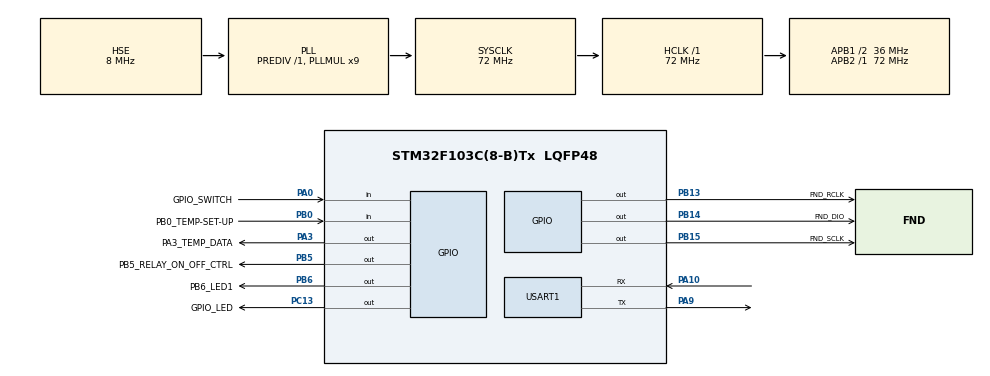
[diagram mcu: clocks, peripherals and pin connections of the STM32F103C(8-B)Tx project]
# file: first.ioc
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Mcu.Family=STM32F1
Mcu.Name=STM32F103C(8-B)Tx
Mcu.Package=LQFP48
NVIC.PriorityGroup=NVIC_PRIORITYGROUP_4
NVIC.TIM2_IRQn=true\:0\:0\:false\:false\:true\:true\:true\:true
PA0-WKUP.GPIO_Label=GPIO_SWITCH
PA0-WKUP.GPIO_PuPd=GPIO_PULLUP
PA0-WKUP.Signal=GPIO_Input
PA10.Mode=Asynchronous
PA10.Signal=USART1_RX
PA13.Mode=Serial_Wire
PA13.Signal=SYS_JTMS-SWDIO
PA14.Mode=Serial_Wire
PA14.Signal=SYS_JTCK-SWCLK
PA3.GPIO_Label=PA3_TEMP_DATA
PA3.GPIO_ModeDefaultOutputPP=GPIO_MODE_OUTPUT_PP
PA3.GPIO_PuPd=GPIO_PULLUP
PA3.GPIO_Speed=GPIO_SPEED_FREQ_HIGH
PA3.PinState=GPIO_PIN_SET
PA3.Signal=GPIO_Output
PA9.Mode=Asynchronous
PA9.Signal=USART1_TX
PB0.GPIO_Label=PB0_TEMP-SET-UP
PB0.GPIO_Mode=GPIO_MODE_INPUT
PB0.GPIO_PuPd=GPIO_PULLUP
PB0.Signal=GPIO_Input
PB13.GPIO_Label=FND_RCLK
PB13.GPIO_ModeDefaultOutputPP=GPIO_MODE_OUTPUT_PP
PB13.GPIO_PuPd=GPIO_PULLUP
PB13.GPIO_Speed=GPIO_SPEED_FREQ_HIGH
PB13.PinState=GPIO_PIN_SET
PB13.Signal=GPIO_Output
PB14.GPIO_Label=FND_DIO
PB14.GPIO_ModeDefaultOutputPP=GPIO_MODE_OUTPUT_PP
PB14.GPIO_PuPd=GPIO_PULLUP
PB14.GPIO_Speed=GPIO_SPEED_FREQ_HIGH
PB14.PinState=GPIO_PIN_SET
PB14.Signal=GPIO_Output
PB15.GPIO_Label=FND_SCLK
PB15.GPIO_PuPd=GPIO_PULLUP
PB15.GPIO_Speed=GPIO_SPEED_FREQ_HIGH
PB15.PinState=GPIO_PIN_SET
PB15.Signal=GPIO_Output
PB5.GPIO_Label=PB5_RELAY_ON_OFF_CTRL
PB5.GPIO_ModeDefaultOutputPP=GPIO_MODE_OUTPUT_PP
PB5.GPIO_PuPd=GPIO_PULLDOWN
PB5.GPIO_Speed=GPIO_SPEED_FREQ_HIGH
PB5.PinState=GPIO_PIN_RESET
PB5.Signal=GPIO_Output
PB6.GPIO_Label=PB6_LED1
PB6.GPIO_PuPd=GPIO_PULLUP
PB6.PinState=GPIO_PIN_SET
PB6.Signal=GPIO_Output
PC13-TAMPER-RTC.GPIO_Label=GPIO_LED
PC13-TAMPER-RTC.GPIO_PuPd=GPIO_PULLUP
PC13-TAMPER-RTC.GPIO_Speed=GPIO_SPEED_FREQ_HIGH
PC13-TAMPER-RTC.PinState=GPIO_PIN_SET
PC13-TAMPER-RTC.Signal=GPIO_Output
PC14-OSC32_IN.Mode=LSE-External-Oscillator
PC14-OSC32_IN.Signal=RCC_OSC32_IN
PC15-OSC32_OUT.Mode=LSE-External-Oscillator
PC15-OSC32_OUT.Signal=RCC_OSC32_OUT
PD0-OSC_IN.Mode=HSE-External-Oscillator
PD0-OSC_IN.Signal=RCC_OSC_IN
PD1-OSC_OUT.Mode=HSE-External-Oscillator
PD1-OSC_OUT.Signal=RCC_OSC_OUT
ProjectManager.HeapSize=0x200
ProjectManager.StackSize=0x400
ProjectManager.TargetToolchain=STM32CubeIDE
RCC.AHBFreq_Value=72000000
RCC.APB1CLKDivider=RCC_HCLK_DIV2
RCC.APB1Freq_Value=36000000
RCC.APB1TimFreq_Value=72000000
RCC.APB2Freq_Value=72000000
RCC.APB2TimFreq_Value=72000000
RCC.HCLKFreq_Value=72000000
RCC.PLLMUL=RCC_PLL_MUL9
RCC.PLLSourceVirtual=RCC_PLLSOURCE_HSE
RCC.SYSCLKFreq_VALUE=72000000
RCC.SYSCLKSource=RCC_SYSCLKSOURCE_PLLCLK
RCC.USBFreq_Value=72000000
TIM2.AutoReloadPreload=TIM_AUTORELOAD_PRELOAD_DISABLE
TIM2.Period=0xFFFF
TIM2.Prescaler=(72-1)
USART1.VirtualMode=VM_ASYNC
VP_TIM2_VS_ClockSourceINT.Mode=Internal
board=custom

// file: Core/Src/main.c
/* USER CODE BEGIN Header */
/**
  ******************************************************************************
  * @file           : main.c
  * @brief          : Main program body
  ******************************************************************************
  * @attention
  *
  * <h2><center>&copy; Copyright (c) 2024 STMicroelectronics.
  * All rights reserved.</center></h2>
  *
  * This software component is licensed by ST under BSD 3-Clause license,
  * the "License"; You may not use this file except in compliance with the
  * License. You may obtain a copy of the License at:
  *                        opensource.org/licenses/BSD-3-Clause
  *
  ******************************************************************************
  */
/* USER CODE END Header */
#include "main.h"

/* USER CODE BEGIN PTD */
#include <stdio.h>
#include "fnd_controller.h"
#include "ds18b20.h"
#include "heaterController.h"
/* USER CODE END PTD */

TIM_HandleTypeDef htim2;

UART_HandleTypeDef huart1;

void SystemClock_Config(void);
static void MX_GPIO_Init(void);
static void MX_USART1_UART_Init(void);
static void MX_TIM2_Init(void);

/* USER CODE BEGIN 0 */
int _write(int file, char * p, int len)
{
	HAL_UART_Transmit(&huart1, (uint8_t *)p, len, 10);
	return len;
}
/* USER CODE END 0 */

int main(void)
{

  /* MCU Configuration--------------------------------------------------------*/

  /* Reset of all peripherals, Initializes the Flash interface and the Systick. */
  HAL_Init();

  /* Configure the system clock */
  SystemClock_Config();

  /* Initialize all configured peripherals */
  MX_GPIO_Init();
  MX_USART1_UART_Init();
  MX_TIM2_Init();
  /* USER CODE BEGIN 2 */
  /*
    GPIO_InitTypeDef GPIO_InitStruct = {0};
    GPIO_InitStruct.Pin = GPIO_LED_Pin;
    GPIO_InitStruct.Mode = GPIO_MODE_OUTPUT_PP;
    GPIO_InitStruct.Pull = GPIO_PULLDOWN;
    GPIO_InitStruct.Speed = GPIO_SPEED_FREQ_HIGH;
    HAL_GPIO_Init(GPIO_LED_GPIO_Port, &GPIO_InitStruct);
  	*/
    //volatile unsigned int * reg2 = 0x40011004;
    //*reg2 = (*reg2 & ~(15UL << 20U)) | (3U << 20U);

  //HAL_TIM_Base_Start(&htim2);
  //HAL_TIM_Base_Start_IT(&htim2);
  init_fnd();
  Ds18b20_Init();
  /* USER CODE END 2 */

  /* Infinite loop */
  /* USER CODE BEGIN WHILE */
  while (1)
  {

	  /*
		for (int i = 0; i <= 9999; i++) {

			digit4_temper(i, 450); //send counter 0-9999 with delay 50 cicles and hide zero

		}*/

	  Ds18b20_ManualConvert();
	  if(getCurrentTemper() > 50 && getHeaterState() == t_ON)
	  {
		  heaterControll(t_OFF);
	  }
	  else if(getCurrentTemper() < 45 && getHeaterState() == t_OFF)
	  {
		  heaterControll(t_ON);
	  }

	  //digit4_temper((int)ds18b20[0].Temperature * 10, 5000);
	  //HAL_GPIO_TogglePin(PB5_RELAY_ON_OFF_CTRL_GPIO_Port, PB5_RELAY_ON_OFF_CTRL_Pin);
	  //HAL_Delay(2000);

    /* USER CODE END WHILE */

  }
}

void SystemClock_Config(void)
{
  RCC_OscInitTypeDef RCC_OscInitStruct = {0};
  RCC_ClkInitTypeDef RCC_ClkInitStruct = {0};

  /** Initializes the RCC Oscillators according to the specified parameters
  * in the RCC_OscInitTypeDef structure.
  */
  RCC_OscInitStruct.OscillatorType = RCC_OSCILLATORTYPE_HSE;
  RCC_OscInitStruct.HSEState = RCC_HSE_ON;
  RCC_OscInitStruct.HSEPredivValue = RCC_HSE_PREDIV_DIV1;
  RCC_OscInitStruct.HSIState = RCC_HSI_ON;
  RCC_OscInitStruct.PLL.PLLState = RCC_PLL_ON;
  RCC_OscInitStruct.PLL.PLLSource = RCC_PLLSOURCE_HSE;
  RCC_OscInitStruct.PLL.PLLMUL = RCC_PLL_MUL9;
  if (HAL_RCC_OscConfig(&RCC_OscInitStruct) != HAL_OK)
  {
    Error_Handler();
  }

  /** Initializes the CPU, AHB and APB buses clocks
  */
  RCC_ClkInitStruct.ClockType = RCC_CLOCKTYPE_HCLK|RCC_CLOCKTYPE_SYSCLK
                              |RCC_CLOCKTYPE_PCLK1|RCC_CLOCKTYPE_PCLK2;
  RCC_ClkInitStruct.SYSCLKSource = RCC_SYSCLKSOURCE_PLLCLK;
  RCC_ClkInitStruct.AHBCLKDivider = RCC_SYSCLK_DIV1;
  RCC_ClkInitStruct.APB1CLKDivider = RCC_HCLK_DIV2;
  RCC_ClkInitStruct.APB2CLKDivider = RCC_HCLK_DIV1;

  if (HAL_RCC_ClockConfig(&RCC_ClkInitStruct, FLASH_LATENCY_2) != HAL_OK)
  {
    Error_Handler();
  }
}

static void MX_TIM2_Init(void)
{

  TIM_ClockConfigTypeDef sClockSourceConfig = {0};
  TIM_MasterConfigTypeDef sMasterConfig = {0};

  htim2.Instance = TIM2;
  htim2.Init.Prescaler = (72-1);
  htim2.Init.CounterMode = TIM_COUNTERMODE_UP;
  htim2.Init.Period = 0xFFFF;
  htim2.Init.ClockDivision = TIM_CLOCKDIVISION_DIV1;
  htim2.Init.AutoReloadPreload = TIM_AUTORELOAD_PRELOAD_DISABLE;
  if (HAL_TIM_Base_Init(&htim2) != HAL_OK)
  {
    Error_Handler();
  }
  sClockSourceConfig.ClockSource = TIM_CLOCKSOURCE_INTERNAL;
  if (HAL_TIM_ConfigClockSource(&htim2, &sClockSourceConfig) != HAL_OK)
  {
    Error_Handler();
  }
  sMasterConfig.MasterOutputTrigger = TIM_TRGO_RESET;
  sMasterConfig.MasterSlaveMode = TIM_MASTERSLAVEMODE_DISABLE;
  if (HAL_TIMEx_MasterConfigSynchronization(&htim2, &sMasterConfig) != HAL_OK)
  {
    Error_Handler();
  }

}

static void MX_USART1_UART_Init(void)
{

  huart1.Instance = USART1;
  huart1.Init.BaudRate = 115200;
  huart1.Init.WordLength = UART_WORDLENGTH_8B;
  huart1.Init.StopBits = UART_STOPBITS_1;
  huart1.Init.Parity = UART_PARITY_NONE;
  huart1.Init.Mode = UART_MODE_TX_RX;
  huart1.Init.HwFlowCtl = UART_HWCONTROL_NONE;
  huart1.Init.OverSampling = UART_OVERSAMPLING_16;
  if (HAL_UART_Init(&huart1) != HAL_OK)
  {
    Error_Handler();
  }

}

static void MX_GPIO_Init(void)
{
  GPIO_InitTypeDef GPIO_InitStruct = {0};

  /* GPIO Ports Clock Enable */
  __HAL_RCC_GPIOC_CLK_ENABLE();
  __HAL_RCC_GPIOD_CLK_ENABLE();
  __HAL_RCC_GPIOA_CLK_ENABLE();
  __HAL_RCC_GPIOB_CLK_ENABLE();

  /*Configure GPIO pin Output Level */
  HAL_GPIO_WritePin(GPIO_LED_GPIO_Port, GPIO_LED_Pin, GPIO_PIN_SET);

  /*Configure GPIO pin Output Level */
  HAL_GPIO_WritePin(PA3_TEMP_DATA_GPIO_Port, PA3_TEMP_DATA_Pin, GPIO_PIN_SET);

  /*Configure GPIO pin Output Level */
  HAL_GPIO_WritePin(GPIOB, FND_RCLK_Pin|FND_DIO_Pin|FND_SCLK_Pin|PB6_LED1_Pin, GPIO_PIN_SET);

  /*Configure GPIO pin Output Level */
  HAL_GPIO_WritePin(PB5_RELAY_ON_OFF_CTRL_GPIO_Port, PB5_RELAY_ON_OFF_CTRL_Pin, GPIO_PIN_RESET);

  /*Configure GPIO pin : GPIO_LED_Pin */
  GPIO_InitStruct.Pin = GPIO_LED_Pin;
  GPIO_InitStruct.Mode = GPIO_MODE_OUTPUT_PP;
  GPIO_InitStruct.Pull = GPIO_PULLUP;
  GPIO_InitStruct.Speed = GPIO_SPEED_FREQ_HIGH;
  HAL_GPIO_Init(GPIO_LED_GPIO_Port, &GPIO_InitStruct);

  /*Configure GPIO pin : GPIO_SWITCH_Pin */
  GPIO_InitStruct.Pin = GPIO_SWITCH_Pin;
  GPIO_InitStruct.Mode = GPIO_MODE_INPUT;
  GPIO_InitStruct.Pull = GPIO_PULLUP;
  HAL_GPIO_Init(GPIO_SWITCH_GPIO_Port, &GPIO_InitStruct);

  /*Configure GPIO pin : PA3_TEMP_DATA_Pin */
  GPIO_InitStruct.Pin = PA3_TEMP_DATA_Pin;
  GPIO_InitStruct.Mode = GPIO_MODE_OUTPUT_PP;
  GPIO_InitStruct.Pull = GPIO_PULLUP;
  GPIO_InitStruct.Speed = GPIO_SPEED_FREQ_HIGH;
  HAL_GPIO_Init(PA3_TEMP_DATA_GPIO_Port, &GPIO_InitStruct);

  /*Configure GPIO pin : PB0_TEMP_SET_UP_Pin */
  GPIO_InitStruct.Pin = PB0_TEMP_SET_UP_Pin;
  GPIO_InitStruct.Mode = GPIO_MODE_INPUT;
  GPIO_InitStruct.Pull = GPIO_PULLUP;
  HAL_GPIO_Init(PB0_TEMP_SET_UP_GPIO_Port, &GPIO_InitStruct);

  /*Configure GPIO pins : FND_RCLK_Pin FND_DIO_Pin FND_SCLK_Pin */
  GPIO_InitStruct.Pin = FND_RCLK_Pin|FND_DIO_Pin|FND_SCLK_Pin;
  GPIO_InitStruct.Mode = GPIO_MODE_OUTPUT_PP;
  GPIO_InitStruct.Pull = GPIO_PULLUP;
  GPIO_InitStruct.Speed = GPIO_SPEED_FREQ_HIGH;
  HAL_GPIO_Init(GPIOB, &GPIO_InitStruct);

  /*Configure GPIO pin : PB5_RELAY_ON_OFF_CTRL_Pin */
  GPIO_InitStruct.Pin = PB5_RELAY_ON_OFF_CTRL_Pin;
  GPIO_InitStruct.Mode = GPIO_MODE_OUTPUT_PP;
  GPIO_InitStruct.Pull = GPIO_PULLDOWN;
  GPIO_InitStruct.Speed = GPIO_SPEED_FREQ_HIGH;
  HAL_GPIO_Init(PB5_RELAY_ON_OFF_CTRL_GPIO_Port, &GPIO_InitStruct);

  /*Configure GPIO pin : PB6_LED1_Pin */
  GPIO_InitStruct.Pin = PB6_LED1_Pin;
  GPIO_InitStruct.Mode = GPIO_MODE_OUTPUT_PP;
  GPIO_InitStruct.Pull = GPIO_PULLUP;
  GPIO_InitStruct.Speed = GPIO_SPEED_FREQ_LOW;
  HAL_GPIO_Init(PB6_LED1_GPIO_Port, &GPIO_InitStruct);

}

void Error_Handler(void)
{
  __disable_irq();
  while (1)
  {
  }
}
